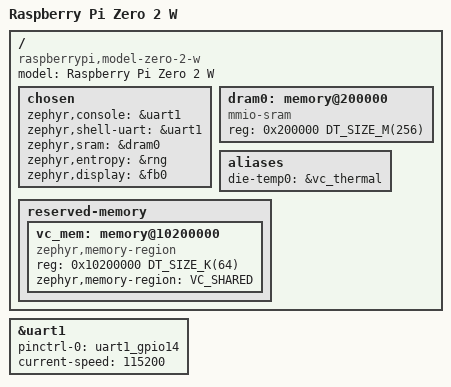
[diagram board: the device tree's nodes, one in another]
/*
 * Copyright (c) 2026 Jonathan Elliot Peace <jep@alphabetiq.com>
 *
 * SPDX-License-Identifier: Apache-2.0
 */

/dts-v1/;

#include <broadcom/bcm2710.dtsi>
#include "rpi_zero_2w-pinctrl.dtsi"

/ {
	model = "Raspberry Pi Zero 2 W";
	compatible = "raspberrypi,model-zero-2-w", "brcm,bcm2710";

	chosen {
		zephyr,console = &uart1;
		zephyr,shell-uart = &uart1;
		zephyr,sram = &dram0;
		zephyr,entropy = &rng;
		zephyr,display = &fb0;
	};

	/*
	 * DRAM window the image is linked into; the base must match the
	 * kernel_address= line in config.txt.
	 */
	dram0: memory@200000 {
		device_type = "memory";
		compatible = "mmio-sram";
		reg = <0x200000 DT_SIZE_M(256)>;
	};

	aliases {
		die-temp0 = &vc_thermal;
	};

	reserved-memory {
		#address-cells = <1>;
		#size-cells = <1>;
		ranges;

		/*
		 * Shared buffer for the VideoCore firmware property
		 * channel -- just above the kernel DRAM window. The
		 * rpi_fw driver maps it uncached; the VPU reads property
		 * requests from it.
		 */
		vc_mem: memory@10200000 {
			compatible = "zephyr,memory-region";
			reg = <0x10200000 DT_SIZE_K(64)>;
			zephyr,memory-region = "VC_SHARED";
		};
	};
};

&uart1 {
	pinctrl-names = "default";
	pinctrl-0 = <&uart1_gpio14>;
	current-speed = <115200>;
	status = "okay";
};
